# prm_irq register map
Vendor: Texas Instruments
Peripheral module from a debugger description file (folder am335x).
Registers are 32-bit, access per field, no defined reset value unless marked. A register's access mark holds for its fields unless they carry their own. Offsets are as the file gives them; lines under a group give offsets from that group; [hi:lo] are bit positions; {n}, {i} and the like mark numbered series; 'fields as' and 'values as' point back to an identical list; <NAME> marks a mode.

## PRM_IRQ
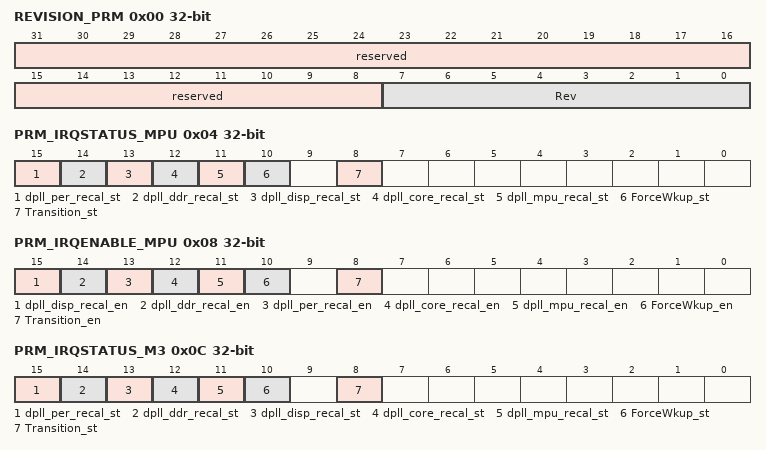
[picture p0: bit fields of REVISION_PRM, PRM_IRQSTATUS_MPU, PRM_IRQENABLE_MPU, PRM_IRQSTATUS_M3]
0x00 REVISION_PRM ro — This register contains the IP revision code for the PRCM
  [31:8] reserved — Reads returns 0.
  [7:0] Rev — IP revision [7:4] Major revision [3:0] Minor revision Examples: 0x10 for 1.0, 0x21 for 2.1
0x04 PRM_IRQSTATUS_MPU — This register provides status on MPU interrupt events. An event is logged whether interrupt generation for the event is enabled or not. SW is required to clear a set bit by writing a '1' into the bit-position to be cleared.
  [15] dpll_per_recal_st rw — interrupt status for usb dpll recaliberation
    0=DIS (Disables dpll recaliberation); 1=EN (ENAbles dpll recaliberation)
  [14] dpll_ddr_recal_st rw — interrupt status for ddr dpll recaliberation
    values as dpll_per_recal_st
  [13] dpll_disp_recal_st rw — interrupt status for disp dpll recaliberation
    values as dpll_per_recal_st
  [12] dpll_core_recal_st rw — interrupt status for core dpll recaliberation
    values as dpll_per_recal_st
  [11] dpll_mpu_recal_st rw — interrupt status for mpu dpll recaliberation
    values as dpll_per_recal_st
  [10] ForceWkup_st rw — Software supervised wakeup completed event interrupt status
    0=IRQ_fal (No interrupt); 1=IRQ_tru (Interrupt is pending)
  [8] Transition_st rw — Software supervised transition completed event interrupt status (any domain)
    0=IRQ_fal (No interrupt); 1=IRQ_tru (Interrupt is pending)
0x08 PRM_IRQENABLE_MPU — This register is used to enable and disable events used to trigger MPU interrupt activation.
  [15] dpll_disp_recal_en rw — Interrupt enable for disp dpll recaliberation
    values as PRM_IRQSTATUS_MPU.dpll_per_recal_st
  [14] dpll_ddr_recal_en rw — Interrupt enable for ddr dpll recaliberation
    values as PRM_IRQSTATUS_MPU.dpll_per_recal_st
  [13] dpll_per_recal_en rw — Interrupt enable for usb dpll recaliberation
    values as PRM_IRQSTATUS_MPU.dpll_per_recal_st
  [12] dpll_core_recal_en rw — Interrupt enable for core dpll recaliberation
    values as PRM_IRQSTATUS_MPU.dpll_per_recal_st
  [11] dpll_mpu_recal_en rw — Interrupt enable for mpu dpll recaliberation
    values as PRM_IRQSTATUS_MPU.dpll_per_recal_st
  [10] ForceWkup_en rw — Software supervised Froce Wakeup completed event interrupt enable
    0=irq_msk (Interrupt is masked); 1=irq_en (Interrupt is enabled)
  [8] Transition_en rw — Software supervised transition completed event interrupt enable (any domain)
    values as ForceWkup_en
0x0C PRM_IRQSTATUS_M3 — This register provides status on MPU interrupt events. An event is logged whether interrupt generation for the event is enabled or not. SW is required to clear a set bit by writing a '1' into the bit-position to be cleared.
  fields as PRM_IRQSTATUS_MPU
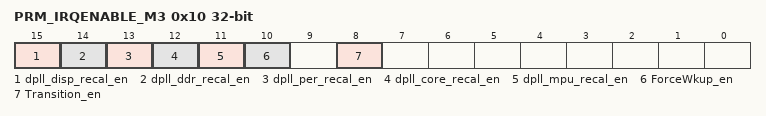
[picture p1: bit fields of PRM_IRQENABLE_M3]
0x10 PRM_IRQENABLE_M3 — This register is used to enable and disable events used to trigger MPU interrupt activation.
  fields as PRM_IRQENABLE_MPU
